# H6 register map
Vendor: Allwinner; Series: H6; File version: 0.1
CPU: CA53 0, little endian, MPU, no FPU, 0 interrupt priority bits
Registers are 32-bit, read-write, reset 0x0 unless marked. A register's access mark holds for its fields unless they carry their own. Offsets are from the block's base; [hi:lo] are bit positions.

## SCR0
Base 0x05005000
Same registers: SCR1 0x05005400
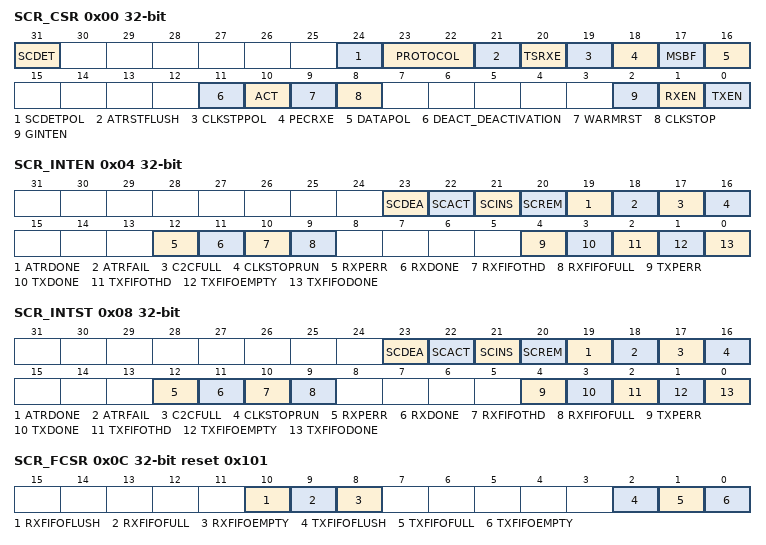
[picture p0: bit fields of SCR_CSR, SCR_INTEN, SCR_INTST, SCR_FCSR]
0x00 SCR_CSR — Smart Card Reader Control and Status Register
  [31] SCDET ro — Smart Card Detected This bit is set to `1` when the scdetect input is active at least for a debounce time.
  [24] SCDETPOL — Smart Card Detect Polarity This bit set polarity of scdetect signal. 0: Low Active 1: High Active
    0=Low (Low Active); 1=High Active
  [23:22] PROTOCOL — Protocol Selection (PTLSEL) 00: T=0. 01: T=1, no character repeating and no guard time is used when T=1 protocol is selected. 10: Reserved 11: Reserved
    0=T_equals_0 (T=0.); 1=T_equals_1 (T=1, no character repeating and no guard time is used when T=1 protocol is selected.)
  [21] ATRSTFLUSH — ATR Start Flush FIFO When enabled, both FIFOs are flushed before the ATR is started.
  [20] TSRXE — TS Receive Enable When set to `1`, the TS character (the first ATR character) will be store in RXFIFO during card session.
  [19] CLKSTPPOL — Clock Stop Polarity The value of the scclk output during the clock stop state.
  [18] PECRXE — Parity Error Character Receive Enable Enables storage of the characters received with wrong parity in RX FIFO.
  [17] MSBF — MSB First When high, inverse bit ordering convention (msb to lsb) is used.
  [16] DATAPOL — Data Plorarity When high, inverse level convention is used (A=`1`, Z=`0`).
  [11] DEACT_DEACTIVATION — Setting of this bit initializes the deactivation sequence. When the deactivation is finished, the DEACT bit is automatically cleared.
  [10] ACT — Activation. Setting of this bit initializes the activation sequence. When the activation is finished, the ACT bit is automatically cleared.
  [9] WARMRST — Warm Reset Command. Writing `1` to this bit initializes Warm Reset of the Smart Card. This bit is always read as `0`.
  [8] CLKSTOP — Clock Stop. When this bit is asserted and the smart card I/O line is in `Z` state, the SCR core stops driving of the smart card clock signal after the CLKSTOPDELAY time expires. The smart card clock is restarted immediately after the CLKSTOP signal is deasserted. New character transmission can be started after CLKSTARTDELAY time. The expiration of both times is signaled by the CLKSTOPRUN bit in the interrupt registers.
  [2] GINTEN — Global Interrupt Enable. When high, IRQ output assertion is enabled.
  [1] RXEN — Receiving Enable. When enabled the characters sent by the Smart Card are received by the UART and stored in RX FIFO. Receiving is internally disabled while a transmission is in progress.
  [0] TXEN — Transmission Enable. When enabled the characters are read from TX FIFO and transmitted through UART to the Smart Card.
0x04 SCR_INTEN — Smart Card Reader Interrupt Enable Register 1
  [23] SCDEA — Smart Card Deactivation Interrupt Enable.
  [22] SCACT — Smart Card Activation Interrupt Enable.
  [21] SCINS — Smart Card Inserted Interrupt Enable.
  [20] SCREM — Smart Card Removed Interrupt Enable.
  [19] ATRDONE — ATR Done Interrupt Enable.
  [18] ATRFAIL — ATR Fail Interrupt Enable.
  [17] C2CFULL — Two Consecutive Characters Limit Interrupt Enable.
  [16] CLKSTOPRUN — Smart Card Clock Stop/Run Interrupt Enable.
  [12] RXPERR — RX Parity Error Interrupt Enable.
  [11] RXDONE — RX Done Interrupt Enable.
  [10] RXFIFOTHD — RX FIFO Threshold Interrupt Enable.
  [9] RXFIFOFULL — RX FIFO Full Interrupt Enable.
  [4] TXPERR — TX Parity Error Interrupt Enable.
  [3] TXDONE — TX Done Interrupt Enable.
  [2] TXFIFOTHD — TX FIFO Threshold Interrupt Enable.
  [1] TXFIFOEMPTY — TX FIFO Empty Interrupt Enable.
  [0] TXFIFODONE — TX FIFO Done Interrupt Enable.
0x08 SCR_INTST — Smart Card Reader Interrupt Status Register 1
  [23] SCDEA write-1-clears — Smart Card Deactivation Interrupt. When enabled, this interrupt is asserted after the Smart Card deactivation sequence is complete. Write `1` to clear.
  [22] SCACT write-1-clears — Smart Card Activation Interrupt. When enabled, this interrupt is asserted after the Smart Card activation sequence is complete. Write `1` to clear.
  [21] SCINS write-1-clears — Smart Card Inserted Interrupt. When enabled, this interrupt is asserted after the smart card insertion. Write `1` to clear.
  [20] SCREM write-1-clears — Smart Card Removed Interrupt. When enabled, this interrupt is asserted after the smart card removal. Write `1` to clear.
  [19] ATRDONE write-1-clears — ATR Done Interrupt. When enabled, this interrupt is asserted after the ATR sequence is successfully completed. Write `1` to clear.
  [18] ATRFAIL write-1-clears — ATR Fail Interrupt. When enabled, this interrupt is asserted if the ATR sequence fails. Write `1` to clear.
  [17] C2CFULL write-1-clears — Two Consecutive Characters Limit Interrupt. When enabled, this interrupt is asserted if the time between two consecutive characters, transmitted between the Smart Card and the Reader in both directions, is equal the Two Characters Delay Limit described below. The C2CFULL interrupt is internally enabled from the ATR start to the deactivation or ATR restart initialization. It is recommended to use this counter to detect unresponsive Smart Cards. Write `1` to clear.
  [16] CLKSTOPRUN write-1-clears — Smart Card Clock Stop/Run Interrupt. When enabled, this interrupt is asserted in two cases: 1. When the smart card clock is stopped. 2. When the new character can be started after the clock restart. To distinguish between the two interrupt cases, we recommend reading the CLKSTOP bit in SCR_CTRL1 register. Write `1` to clear.
  [12] RXPERR write-1-clears — RX Parity Error Interrupt. When enabled, this interrupt is asserted after the character with wrong parity was received when the number of repeated receptions exceeds RXREPEAT value or T=1 protocol is used. Write `1` to clear.
  [11] RXDONE write-1-clears — RX Done Interrupt. When enabled, this interrupt is asserted after a character was received from the Smart Card. Write `1` to clear.
  [10] RXFIFOTHD write-1-clears — RX FIFO Threshold Interrupt. When enabled, this interrupt is asserted if the number of bytes in RX FIFO is equal or exceeds the RX FIFO threshold. Write `1` to clear.
  [9] RXFIFOFULL write-1-clears — RX FIFO Full Interrupt. When enabled, this interrupt is asserted if the RX FIFO is filled up. Write `1` to clear.
  [4] TXPERR write-1-clears — TX Parity Error Interrupt. When enabled, this interrupt is asserted if the Smart Card signals wrong character parity during the guard time after the character transmission was repeated TXREPEAT times or T=1 protocol is used. Write `1` to clear.
  [3] TXDONE write-1-clears — TX Done Interrupt. When enabled, this interrupt is asserted after one character was transmitted to the smart card. Write `1` to clear.
  [2] TXFIFOTHD write-1-clears — TX FIFO Threshold Interrupt. When enabled, this interrupt is asserted if the number of bytes in TX FIFO is equal or less than the TX FIFO threshold. Write `1` to clear.
  [1] TXFIFOEMPTY write-1-clears — TX FIFO Empty Interrupt. When enabled, this interrupt is asserted if the TX FIFO is emptied out. Write `1` to clear.
  [0] TXFIFODONE write-1-clears — TX FIFO Done Interrupt. When enabled, this interrupt is asserted after all bytes from TX FIFO ware transferred to the Smart Card. Write `1` to clear.
0x0C SCR_FCSR reset 0x101 — Smart Card Reader FIFO Control and Status Register
  [10] RXFIFOFLUSH — Flush RX FIFO. RX FIFO is flushed, when `1` is written to this bit.
  [9] RXFIFOFULL ro
  [8] RXFIFOEMPTY ro
  [2] TXFIFOFLUSH — Flush TX FIFO. TX FIFO is flushed, when `1` is written to this bit.
  [1] TXFIFOFULL ro
  [0] TXFIFOEMPTY ro
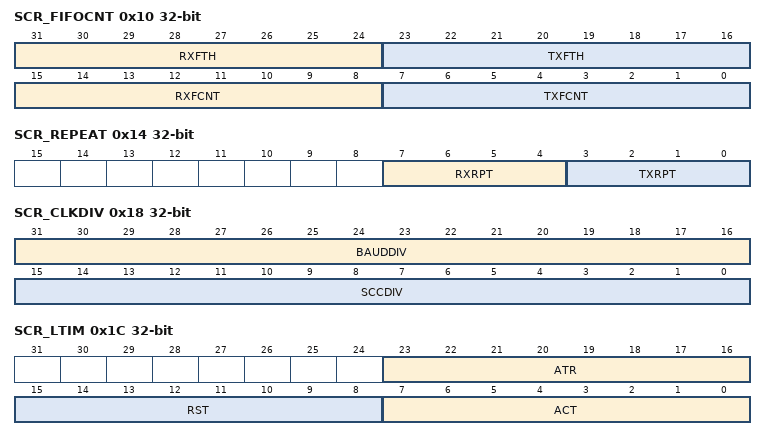
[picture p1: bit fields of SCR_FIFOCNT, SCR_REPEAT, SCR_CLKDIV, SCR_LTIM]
0x10 SCR_FIFOCNT
  [31:24] RXFTH — RX FIFO Threshold These bits set the interrupt threshold of RX FIFO. The interrupt is asserted when the number of bytes it receives is equal to, or exceeds the threshold.
  [23:16] TXFTH — TX FIFO Threshold These bits set the interrupt threshold of TX FIFO. The interrupt is asserted when the number of bytes in TX FIFO is equal to or less than the threshold.
  [15:8] RXFCNT ro — RX FIFO Counter These bits provide the number of bytes stored in the RXFIFO.
  [7:0] TXFCNT ro — TX FIFO Counter These bits provide the number of bytes stored in the TXFIFO.
0x14 SCR_REPEAT
  [7:4] RXRPT — RX Repeat This is a 4-bit register that specifies the number of attempts to request character re-transmission after wrong parity was detected. The re-transmission of the character is requested using the error signal during the guard time.
  [3:0] TXRPT — TX Repeat This is a 4-bit register that specifies the number of attempts to re-transmit the character after the Smart Card signals the wrong parity during the guard time.
0x18 SCR_CLKDIV
  [31:16] BAUDDIV — Baud Clock Divisor. This 16-bit register defines the divisor value used to generate the Baud Clock impulses from the system clock.
  [15:0] SCCDIV — Smart Card Clock Divisor. This 16-bit register defines the divisor value used to generate the Smart Card Clock from the system clock. is the frequency of Smart Card Clock Signal. is the frequency of APB Clock.
0x1C SCR_LTIM — Smart Card Reader Line Time Register
  [23:16] ATR — ATR Start Limit. This 16-bit register defines the maximum time between the rising edge of the signal and the start of ATR response. ATR Start Limit = 128* ATR* .
  [15:8] RST — Reset Duration. This 16-bit register sets the duration of the Smart Card reset sequence. This value is same for the cold and warm reset. Cold/Warm Reset Duration = 128* RST* .
  [7:0] ACT — Activation/Deactivation Time. This 16-bit register sets the duration of each part of the activation and deactivation sequence. Activation/Deactivation Duration = 128* ACT * . is the Smart Card Clock Cycle.
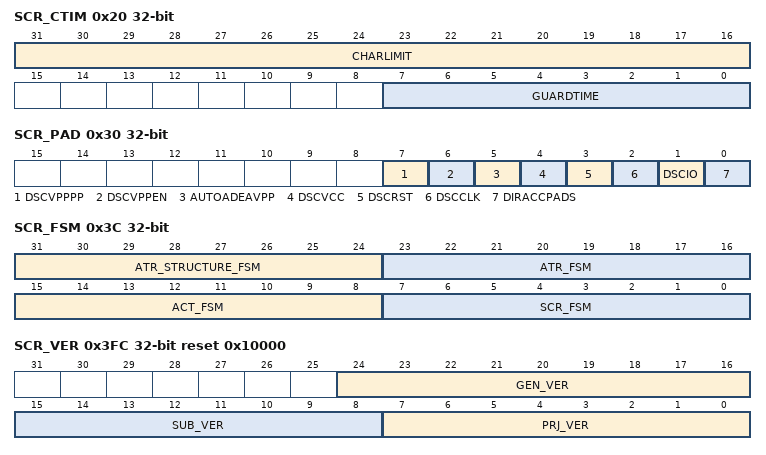
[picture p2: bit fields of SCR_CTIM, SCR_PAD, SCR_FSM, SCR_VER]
0x20 SCR_CTIM — Smart Card Reader Character Time Register
  [31:16] CHARLIMIT — Character Limit. This 16-bit register sets the maximum time between the leading edges of two consecutive characters. The value is ETUs.
  [7:0] GUARDTIME — Character Guard time. This 8-bit register sets a delay at the end of each character transmitted from the Smart Card Reader to the Smart Card. The value is in ETUs. The parity error is besides signaled during the guard time.
0x30 SCR_PAD
  [7] DSCVPPPP — Direct Smart Card Vpp Pause/Prog. It provides direct access to SCVPPPP output.
  [6] DSCVPPEN — Direct Smart Card Vpp Enable. It provides direct access to SCVPPEN output.
  [5] AUTOADEAVPP — Automatic Vpp Handling. When high, it enables automatic handling of DSVPPEN and DSVPPPP signals during activation and deactivation sequence.
  [4] DSCVCC — Direct Smart Card VCC. When DIRACCPADS=`1`, the DSCVCC bit provides direct access to SCVCC pad.
  [3] DSCRST — Direct Smart Card Clock. When DIRACCPADS=`1`, the DSCRST bit provides direct access to SCRST pad.
  [2] DSCCLK — Direct Smart Card Clock. When DIRACCPADS=`1`, the DSCCLK bit provides direct access to SCCLK pad.
  [1] DSCIO — Direct Smart Card Input/Output. When DIRACCPADS=`1`, the DSCIO bit provides direct access to SCIO pad.
  [0] DIRACCPADS — Direct Access to Smart Card Pads. When high, it disables a serial interface functionality and enables direct control of the smart card pads using following 4 bits.
0x3C SCR_FSM — Smart Card Reader FSM Register
  [31:24] ATR_STRUCTURE_FSM ro, [23:16] ATR_FSM ro, [15:8] ACT_FSM ro, [7:0] SCR_FSM ro
0x40 SCR_DT reset 0x3FF — Smart Card Reader Debounce Time Register
  [31:0] SCR_DEBOUNCE_TIME — Set the debounce time value for card insert detecting.The time uint is the cycle of SCCLK.
0x100 SCR_FIFO — Smart Card Reader RX and TX FIFO Access Point
  [7:0] FIFO_DATA — This 8-bit register provides access to the RX and TX FIFO buffers. The TX FIFO is accessed during the APB write transfer. The RX FIFO is accessed during the APB read transfer.
0x3FC SCR_VER reset 0x10000
  [24:16] GEN_VER ro — Generation version.
  [15:8] SUB_VER ro — Sub version.
  [7:0] PRJ_VER ro — Project version.
